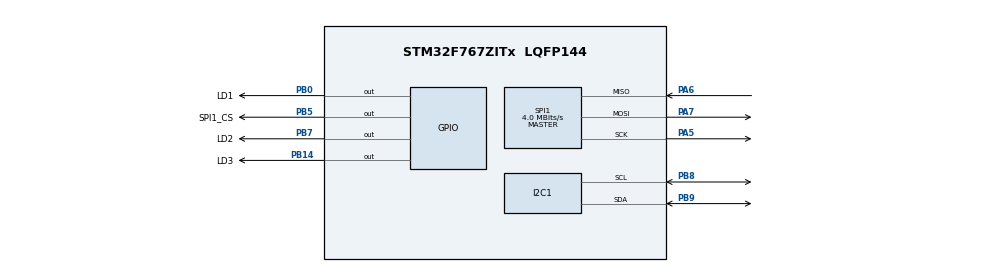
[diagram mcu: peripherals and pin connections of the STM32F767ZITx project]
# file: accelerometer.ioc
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Mcu.Family=STM32F7
Mcu.Name=STM32F767ZITx
Mcu.Package=LQFP144
NVIC.PriorityGroup=NVIC_PRIORITYGROUP_4
PA5.Mode=Full_Duplex_Master
PA5.Signal=SPI1_SCK
PA6.Mode=Full_Duplex_Master
PA6.Signal=SPI1_MISO
PA7.Mode=Full_Duplex_Master
PA7.Signal=SPI1_MOSI
PB0.GPIO_Label=LD1
PB0.Signal=GPIO_Output
PB14.GPIO_Label=LD3
PB14.Signal=GPIO_Output
PB5.GPIO_Label=SPI1_CS
PB5.Signal=GPIO_Output
PB7.GPIO_Label=LD2
PB7.Signal=GPIO_Output
PB8.Mode=I2C
PB8.Signal=I2C1_SCL
PB9.Mode=I2C
PB9.Signal=I2C1_SDA
ProjectManager.HeapSize=0x200
ProjectManager.StackSize=0x400
ProjectManager.TargetToolchain=STM32CubeIDE
RCC.HSE_VALUE=25000000
RCC.HSI_VALUE=16000000
RCC.LSE_VALUE=32768
RCC.USBFreq_Value=96000000
RCC.VCOOutputFreq_Value=192000000
SPI1.BaudRatePrescaler=SPI_BAUDRATEPRESCALER_4
SPI1.CLKPolarity=SPI_POLARITY_HIGH
SPI1.CalculateBaudRate=4.0 MBits/s
SPI1.Direction=SPI_DIRECTION_2LINES
SPI1.Mode=SPI_MODE_MASTER
SPI1.VirtualType=VM_MASTER
board=custom

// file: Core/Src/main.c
/* USER CODE BEGIN Header */
/**
  ******************************************************************************
  * @file           : main.c
  * @brief          : Main program body
  ******************************************************************************
  * @attention
  *
  * Copyright (c) 2024 STMicroelectronics.
  * All rights reserved.
  *
  * This software is licensed under terms that can be found in the LICENSE file
  * in the root directory of this software component.
  * If no LICENSE file comes with this software, it is provided AS-IS.
  *
  ******************************************************************************
  */
/* USER CODE END Header */
#include "main.h"

/* USER CODE BEGIN Includes */
#include "ADXL.h"
/* USER CODE END Includes */

I2C_HandleTypeDef hi2c1;

SPI_HandleTypeDef hspi1;

/* USER CODE BEGIN PV */
ADXL_InitTypeDef ADXL;
adxlStatus adxlSts;
int16_t accelData[3];
/* USER CODE END PV */

void SystemClock_Config(void);
static void MX_GPIO_Init(void);
static void MX_I2C1_Init(void);
static void MX_SPI1_Init(void);

int main(void)
{

  /* MCU Configuration--------------------------------------------------------*/

  /* Reset of all peripherals, Initializes the Flash interface and the Systick. */
  HAL_Init();

  /* Configure the system clock */
  SystemClock_Config();

  /* Initialize all configured peripherals */
  MX_GPIO_Init();
  MX_I2C1_Init();
  MX_SPI1_Init();
  /* USER CODE BEGIN 2 */
  if (ADXL_Init(&ADXL)!= ADXL_OK){
	  HAL_GPIO_WritePin(LD3_GPIO_Port, LD3_Pin, GPIO_PIN_SET);
	  Error_Handler();
  }

  /* USER CODE END 2 */

  /* Infinite loop */
  /* USER CODE BEGIN WHILE */
  while (1)
  {
//	  HAL_GPIO_TogglePin(LD1_GPIO_Port, LD1_Pin);
	  HAL_GPIO_TogglePin(LD2_GPIO_Port, LD2_Pin);
	  //ADXL_getAccel(accelData, OUTPUT_SIGNED);
//	  HAL_GPIO_TogglePin(LD3_GPIO_Port, LD3_Pin);
	  HAL_Delay(200);
    /* USER CODE END WHILE */

  }
}

void SystemClock_Config(void)
{
  RCC_OscInitTypeDef RCC_OscInitStruct = {0};
  RCC_ClkInitTypeDef RCC_ClkInitStruct = {0};

  /** Configure the main internal regulator output voltage
  */
  __HAL_RCC_PWR_CLK_ENABLE();
  __HAL_PWR_VOLTAGESCALING_CONFIG(PWR_REGULATOR_VOLTAGE_SCALE3);

  /** Initializes the RCC Oscillators according to the specified parameters
  * in the RCC_OscInitTypeDef structure.
  */
  RCC_OscInitStruct.OscillatorType = RCC_OSCILLATORTYPE_HSI;
  RCC_OscInitStruct.HSIState = RCC_HSI_ON;
  RCC_OscInitStruct.HSICalibrationValue = RCC_HSICALIBRATION_DEFAULT;
  RCC_OscInitStruct.PLL.PLLState = RCC_PLL_NONE;
  if (HAL_RCC_OscConfig(&RCC_OscInitStruct) != HAL_OK)
  {
    Error_Handler();
  }

  /** Initializes the CPU, AHB and APB buses clocks
  */
  RCC_ClkInitStruct.ClockType = RCC_CLOCKTYPE_HCLK|RCC_CLOCKTYPE_SYSCLK
                              |RCC_CLOCKTYPE_PCLK1|RCC_CLOCKTYPE_PCLK2;
  RCC_ClkInitStruct.SYSCLKSource = RCC_SYSCLKSOURCE_HSI;
  RCC_ClkInitStruct.AHBCLKDivider = RCC_SYSCLK_DIV1;
  RCC_ClkInitStruct.APB1CLKDivider = RCC_HCLK_DIV1;
  RCC_ClkInitStruct.APB2CLKDivider = RCC_HCLK_DIV1;

  if (HAL_RCC_ClockConfig(&RCC_ClkInitStruct, FLASH_LATENCY_0) != HAL_OK)
  {
    Error_Handler();
  }
}

static void MX_I2C1_Init(void)
{

  hi2c1.Instance = I2C1;
  hi2c1.Init.Timing = 0x00303D5B;
  hi2c1.Init.OwnAddress1 = 0;
  hi2c1.Init.AddressingMode = I2C_ADDRESSINGMODE_7BIT;
  hi2c1.Init.DualAddressMode = I2C_DUALADDRESS_DISABLE;
  hi2c1.Init.OwnAddress2 = 0;
  hi2c1.Init.OwnAddress2Masks = I2C_OA2_NOMASK;
  hi2c1.Init.GeneralCallMode = I2C_GENERALCALL_DISABLE;
  hi2c1.Init.NoStretchMode = I2C_NOSTRETCH_DISABLE;
  if (HAL_I2C_Init(&hi2c1) != HAL_OK)
  {
    Error_Handler();
  }

  /** Configure Analogue filter
  */
  if (HAL_I2CEx_ConfigAnalogFilter(&hi2c1, I2C_ANALOGFILTER_ENABLE) != HAL_OK)
  {
    Error_Handler();
  }

  /** Configure Digital filter
  */
  if (HAL_I2CEx_ConfigDigitalFilter(&hi2c1, 0) != HAL_OK)
  {
    Error_Handler();
  }

}

static void MX_SPI1_Init(void)
{

  /* SPI1 parameter configuration*/
  hspi1.Instance = SPI1;
  hspi1.Init.Mode = SPI_MODE_MASTER;
  hspi1.Init.Direction = SPI_DIRECTION_2LINES;
  hspi1.Init.DataSize = SPI_DATASIZE_8BIT;
  hspi1.Init.CLKPolarity = SPI_POLARITY_HIGH;
  hspi1.Init.CLKPhase = SPI_PHASE_2EDGE;
  hspi1.Init.NSS = SPI_NSS_SOFT;
  hspi1.Init.BaudRatePrescaler = SPI_BAUDRATEPRESCALER_8;
  hspi1.Init.FirstBit = SPI_FIRSTBIT_MSB;
  hspi1.Init.TIMode = SPI_TIMODE_DISABLE;
  hspi1.Init.CRCCalculation = SPI_CRCCALCULATION_DISABLE;
  hspi1.Init.CRCPolynomial = 7;
  hspi1.Init.CRCLength = SPI_CRC_LENGTH_DATASIZE;
  hspi1.Init.NSSPMode = SPI_NSS_PULSE_DISABLE;
  if (HAL_SPI_Init(&hspi1) != HAL_OK)
  {
    Error_Handler();
  }

}

static void MX_GPIO_Init(void)
{
  GPIO_InitTypeDef GPIO_InitStruct = {0};

  /* GPIO Ports Clock Enable */
  __HAL_RCC_GPIOA_CLK_ENABLE();
  __HAL_RCC_GPIOB_CLK_ENABLE();

  /*Configure GPIO pin Output Level */
  HAL_GPIO_WritePin(GPIOB, LD1_Pin|LD3_Pin|SPI1_CS_Pin|LD2_Pin, GPIO_PIN_RESET);

  /*Configure GPIO pins : LD1_Pin LD3_Pin SPI1_CS_Pin LD2_Pin */
  GPIO_InitStruct.Pin = LD1_Pin|LD3_Pin|SPI1_CS_Pin|LD2_Pin;
  GPIO_InitStruct.Mode = GPIO_MODE_OUTPUT_PP;
  GPIO_InitStruct.Pull = GPIO_NOPULL;
  GPIO_InitStruct.Speed = GPIO_SPEED_FREQ_LOW;
  HAL_GPIO_Init(GPIOB, &GPIO_InitStruct);

}

void Error_Handler(void)
{
  __disable_irq();
  while (1)
  {
  }
}
